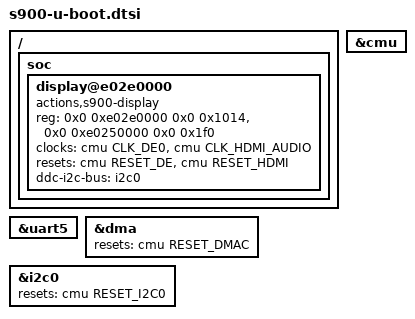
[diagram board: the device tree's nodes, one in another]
// SPDX-License-Identifier: GPL-2.0+
/*
 */

/{
	soc {
		bootph-all;

		/* Display engine and HDMI transmitter, U-Boot only (s900_video) */
		display@e02e0000 {
			compatible = "actions,s900-display";
			reg = <0x0 0xe02e0000 0x0 0x1014>,
			      <0x0 0xe0250000 0x0 0x1f0>;
			reg-names = "de", "hdmi";
			clocks = <&cmu CLK_DE0>, <&cmu CLK_HDMI_AUDIO>;
			clock-names = "de", "hdmia";
			resets = <&cmu RESET_DE>, <&cmu RESET_HDMI>;
			reset-names = "de", "hdmi";
			ddc-i2c-bus = <&i2c0>;
		};
	};
};

&uart5 {
	bootph-all;
};

&cmu {
	bootph-all;
};

/* owl_mmc releases the DMAC reset like the vendor U-Boot owl_dma_init() */
&dma {
	resets = <&cmu RESET_DMAC>;
};

/* owl_i2c pulses it like the vendor U-Boot owl_i2c_init(): it may come up held */
&i2c0 {
	resets = <&cmu RESET_I2C0>;
};
